# FM33FK5XX register map
File version: 1.0
CPU: Cortex-M33 r1p0, little endian, MPU, FPU, 3 interrupt priority bits
Registers are 32-bit, read-write, reset 0x0 unless marked. A register's access mark holds for its fields unless they carry their own. Offsets are from the block's base; [hi:lo] are bit positions; {n}, {i} and the like mark numbered series.

## CDIF — CDIF module information
Base 0x4001EC00
0x00 CR
  [0] INTF_OEN — INTF_OEN field description
0x04 PRSC
  [2:0] PRSC — PRSC field description

## RMU — RMU module information
Base 0x40002800
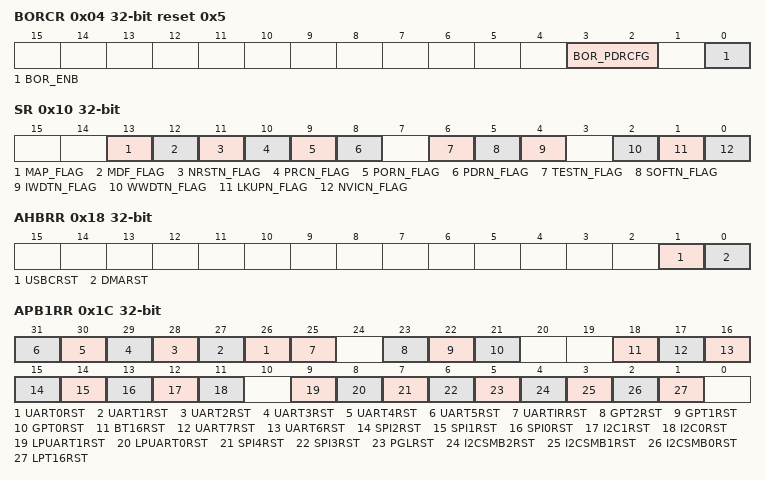
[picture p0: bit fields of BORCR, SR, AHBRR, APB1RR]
0x04 BORCR reset 0x5 — BORControlRegister
  [3:2] BOR_PDRCFG — BOR_PDRCFG field description
  [0] BOR_ENB — BOR_ENB field description
0x08 CFGR — ResetConfigRegister
  [1] LKUPRST_EN — LKUPRST_EN field description
0x0C SFTRST wo — SoftwareResetRegister
  [31:0] SOFTRST — SOFTRST field description
0x10 SR — ResetFlagRegister
  [13] MAP_FLAG — MAP_FLAG field description
  [12] MDF_FLAG — MDF_FLAG field description
  [11] NRSTN_FLAG — NRSTN_FLAG field description
  [10] PRCN_FLAG — PRCN_FLAG field description
  [9] PORN_FLAG — PORN_FLAG field description
  [8] PDRN_FLAG — PDRN_FLAG field description
  [6] TESTN_FLAG — TESTN_FLAG field description
  [5] SOFTN_FLAG — SOFTN_FLAG field description
  [4] IWDTN_FLAG — IWDTN_FLAG field description
  [2] WWDTN_FLAG — WWDTN_FLAG field description
  [1] LKUPN_FLAG — LKUPN_FLAG field description
  [0] NVICN_FLAG — NVICN_FLAG field description
0x14 PRER wo — PeripheralResetEnableRegister
  [31:0] PERHRSTEN — PERHRSTEN field description
0x18 AHBRR — AHBPeripheralsResetRegister
  [1] USBCRST — USBCRST field description
  [0] DMARST — DMARST field description
0x1C APB1RR — APBPeripheralsResetRegister1
  [n+26] UART{n}RST (n=0..5) — UART{n}RST field description
  [25] UARTIRRST — UARTIRRST field description
  [23] GPT2RST — GPT2RST field description
  [22] GPT1RST — GPT1RST field description
  [21] GPT0RST — GPT0RST field description
  [18] BT16RST — BT16RST field description
  [17] UART7RST — UART7RST field description
  [16] UART6RST — UART6RST field description
  [15] SPI2RST — SPI2RST field description
  [14] SPI1RST — SPI1RST field description
  [13] SPI0RST — SPI0RST field description
  [12] I2C1RST — I2C1RST field description
  [11] I2C0RST — I2C0RST field description
  [9] LPUART1RST — LPUART1RST field description
  [8] LPUART0RST — LPUART0RST field description
  [7] SPI4RST — SPI4RST field description
  [6] SPI3RST — SPI3RST field description
  [5] PGLRST — PGLRST field description
  [4] I2CSMB2RST — I2CSMB2RST field description
  [3] I2CSMB1RST — I2CSMB1RST field description
  [2] I2CSMB0RST — I2CSMB0RST field description
  [1] LPT16RST — LPT16RST field description
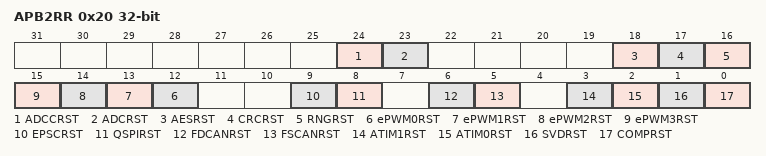
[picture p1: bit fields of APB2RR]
0x20 APB2RR — APBPeripheralsResetRegister2
  [24] ADCCRST — ADCCRST field description
  [23] ADCRST — ADCRST field description
  [18] AESRST — AESRST field description
  [17] CRCRST — CRCRST field description
  [16] RNGRST — RNGRST field description
  [n+12] ePWM{n}RST (n=0..3) — ePWM{n}RST field description
  [9] EPSCRST — EPSCRST field description
  [8] QSPIRST — QSPIRST field description
  [6] FDCANRST — FDCANRST field description
  [5] FSCANRST — FSCANRST field description
  [3] ATIM1RST — ATIM1RST field description
  [2] ATIM0RST — ATIM0RST field description
  [1] SVDRST — SVDRST field description
  [0] COMPRST — COMPRST field description

## IWDT — IWDT module information
Base 0x40021000
0x00 SERV wo — IWDTServiceRegister
  [31:0] SERV — SERV field description
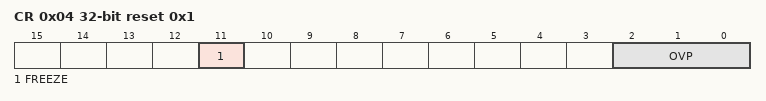
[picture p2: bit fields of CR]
0x04 CR reset 0x1 — IWDTConfigRegister
  [11] FREEZE — FREEZE field description
  [2:0] OVP — OVP field description
0x08 CNT ro — IWDTCounterRegister
  [11:0] CNT — CNT field description
0x0C WIN — IWDTWindowRegister
  [11:0] WIN — WIN field description
0x10 IER — IWDTInterruptEnableRegister
  [0] IE — IE field description
0x14 ISR — IWDTInterruptStatusRegister
  [0] WINF — WINF field description

## WWDT — WWDT module information
Base 0x40011800
0x00 CR wo — WWDTControlRegister
  [7:0] CON — CON field description
0x04 CFGR reset 0x3 — WWDTConfigRegister
  [2:0] CFG — CFG field description
0x08 CNT ro — WWDTCounterRegister
  [9:0] CNT — CNT field description
0x0C IER — WWDTInterruptEnableRegister
  [0] IE — IE field description
0x10 ISR — WWDTInterruptStatusRegister
  [0] NOVF — NOVF field description
0x14 PSC ro — WWDTPrescalerRegister
  [11:0] DIV_CNT — DIV_CNT field description
